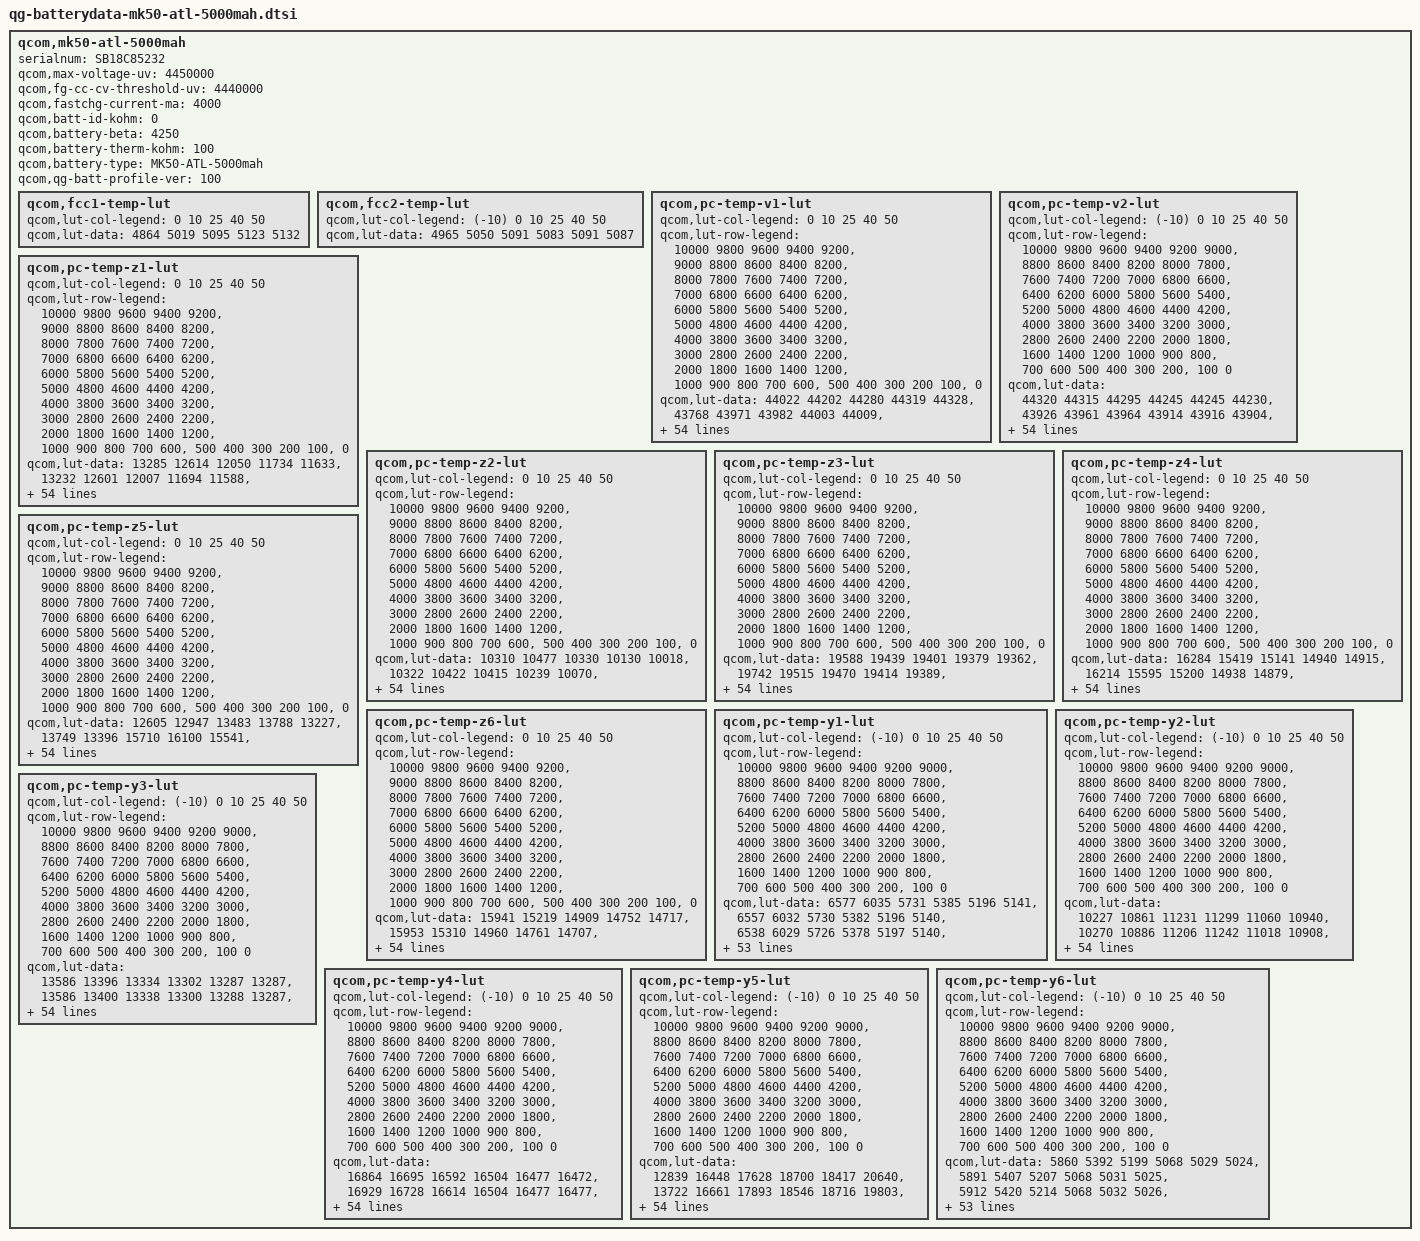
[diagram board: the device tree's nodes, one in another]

qcom,mk50-atl-5000mah {
    serialnum = "SB18C85232";
    qcom,max-voltage-uv = <4450000>;
    qcom,fg-cc-cv-threshold-uv = <4440000>;
    qcom,fastchg-current-ma = <4000>;
    qcom,batt-id-kohm = <0>;
    qcom,battery-beta = <4250>;
    qcom,battery-therm-kohm = <100>;
    qcom,battery-type = "MK50-ATL-5000mah";
    qcom,qg-batt-profile-ver = <100>;

	qcom,fcc1-temp-lut {
		qcom,lut-col-legend = <0 10 25 40 50>;
		qcom,lut-data = <4864 5019 5095 5123 5132>;
	};

	qcom,fcc2-temp-lut {
		qcom,lut-col-legend = <(-10) 0 10 25 40 50>;
		qcom,lut-data = <4965 5050 5091 5083 5091 5087>;
	};

	qcom,pc-temp-v1-lut {
		qcom,lut-col-legend = <0 10 25 40 50>;
		qcom,lut-row-legend = <10000 9800 9600 9400 9200>,
			<9000 8800 8600 8400 8200>,
			<8000 7800 7600 7400 7200>,
			<7000 6800 6600 6400 6200>,
			<6000 5800 5600 5400 5200>,
			<5000 4800 4600 4400 4200>,
			<4000 3800 3600 3400 3200>,
			<3000 2800 2600 2400 2200>,
			<2000 1800 1600 1400 1200>,
			<1000 900 800 700 600>,
			<500 400 300 200 100>,
			<0>;
		qcom,lut-data = <44022 44202 44280 44319 44328>,
			<43768 43971 43982 44003 44009>,
			<43525 43723 43742 43757 43756>,
			<43289 43479 43517 43532 43534>,
			<43052 43241 43282 43304 43310>,
			<42808 43001 43042 43072 43078>,
			<42564 42756 42801 42838 42844>,
			<42324 42509 42556 42596 42606>,
			<42088 42264 42310 42349 42365>,
			<41856 42022 42069 42108 42125>,
			<41628 41786 41831 41872 41886>,
			<41405 41555 41597 41639 41650>,
			<41191 41329 41369 41408 41419>,
			<40988 41112 41146 41180 41192>,
			<40786 40903 40930 40962 40973>,
			<40580 40701 40721 40750 40760>,
			<40375 40500 40521 40548 40556>,
			<40191 40304 40331 40354 40363>,
			<40024 40125 40149 40169 40179>,
			<39868 39967 39984 40000 40009>,
			<39719 39808 39826 39844 39851>,
			<39576 39635 39635 39655 39662>,
			<39423 39453 39393 39384 39384>,
			<39247 39243 39168 39130 39122>,
			<39066 38974 38987 38974 38976>,
			<38889 38760 38833 38854 38871>,
			<38711 38663 38720 38749 38767>,
			<38586 38597 38635 38655 38660>,
			<38515 38532 38557 38567 38560>,
			<38461 38468 38478 38475 38465>,
			<38413 38408 38405 38387 38378>,
			<38370 38349 38338 38311 38300>,
			<38331 38295 38279 38245 38231>,
			<38294 38245 38222 38183 38165>,
			<38258 38203 38172 38123 38101>,
			<38224 38163 38123 38067 38038>,
			<38194 38126 38076 38011 37976>,
			<38159 38088 38032 37959 37916>,
			<38106 38034 37974 37892 37842>,
			<38032 37952 37890 37798 37736>,
			<37942 37851 37788 37687 37613>,
			<37822 37734 37675 37576 37497>,
			<37683 37596 37542 37453 37374>,
			<37528 37428 37379 37296 37212>,
			<37361 37266 37219 37151 37070>,
			<37254 37153 37109 37053 36990>,
			<37203 37115 37071 37020 36961>,
			<37162 37085 37049 36994 36934>,
			<37128 37069 37026 36975 36913>,
			<37095 37033 36990 36926 36855>,
			<37033 36870 36796 36701 36604>,
			<36772 36442 36369 36268 36170>,
			<36265 35853 35792 35692 35593>,
			<35564 35011 35003 34907 34807>,
			<34395 33595 33776 33693 33587>,
			<30000 30000 30000 30000 30000>;
	};

	qcom,pc-temp-v2-lut {
		qcom,lut-col-legend = <(-10) 0 10 25 40 50>;
		qcom,lut-row-legend = <10000 9800 9600 9400 9200 9000>,
			<8800 8600 8400 8200 8000 7800>,
			<7600 7400 7200 7000 6800 6600>,
			<6400 6200 6000 5800 5600 5400>,
			<5200 5000 4800 4600 4400 4200>,
			<4000 3800 3600 3400 3200 3000>,
			<2800 2600 2400 2200 2000 1800>,
			<1600 1400 1200 1000 900 800>,
			<700 600 500 400 300 200>,
			<100 0>;
		qcom,lut-data = <44320 44315 44295 44245 44245 44230>,
			<43926 43961 43964 43914 43916 43904>,
			<43579 43644 43663 43612 43617 43608>,
			<43290 43373 43399 43347 43354 43346>,
			<43052 43141 43168 43113 43124 43117>,
			<42819 42910 42937 42881 42894 42888>,
			<42559 42663 42692 42637 42652 42649>,
			<42296 42415 42445 42392 42409 42408>,
			<42066 42168 42199 42149 42166 42167>,
			<41869 41921 41954 41906 41923 41924>,
			<41662 41685 41713 41669 41685 41686>,
			<41406 41463 41476 41436 41451 41452>,
			<41132 41248 41246 41209 41222 41223>,
			<40907 41037 41024 40987 40999 41000>,
			<40733 40830 40809 40769 40780 40782>,
			<40543 40614 40603 40560 40571 40573>,
			<40256 40380 40406 40357 40368 40370>,
			<39917 40139 40208 40164 40174 40176>,
			<39651 39898 39997 39988 39995 39996>,
			<39453 39657 39777 39822 39824 39823>,
			<39261 39429 39553 39631 39643 39645>,
			<39031 39217 39317 39397 39445 39459>,
			<38791 39020 39098 39165 39243 39267>,
			<38596 38844 38912 38964 39029 39050>,
			<38431 38683 38747 38782 38817 38830>,
			<38302 38532 38601 38633 38657 38666>,
			<38217 38386 38472 38510 38535 38543>,
			<38154 38254 38356 38403 38429 38436>,
			<38095 38137 38251 38303 38329 38335>,
			<38043 38032 38154 38212 38239 38242>,
			<37993 37962 38060 38129 38159 38158>,
			<37941 37917 37965 38054 38087 38083>,
			<37889 37880 37891 37984 38018 38010>,
			<37834 37843 37840 37920 37951 37942>,
			<37778 37808 37799 37860 37883 37873>,
			<37720 37765 37759 37795 37807 37789>,
			<37659 37710 37722 37728 37726 37691>,
			<37596 37648 37678 37657 37640 37593>,
			<37526 37581 37621 37587 37550 37499>,
			<37446 37506 37551 37512 37458 37406>,
			<37358 37420 37462 37427 37369 37318>,
			<37264 37318 37347 37329 37277 37228>,
			<37163 37196 37210 37208 37150 37096>,
			<37071 37050 37054 37073 37015 36956>,
			<36987 36890 36888 36946 36906 36853>,
			<36910 36770 36782 36873 36850 36798>,
			<36866 36731 36749 36858 36838 36786>,
			<36818 36693 36713 36840 36824 36770>,
			<36771 36658 36665 36816 36798 36744>,
			<36721 36610 36579 36758 36733 36660>,
			<36661 36520 36338 36531 36454 36360>,
			<36556 36220 35852 36064 35970 35861>,
			<36334 35595 35181 35437 35327 35210>,
			<35882 34640 34171 34600 34453 34322>,
			<35058 33288 32721 33351 33175 33035>,
			<34064 31548 27372 27953 28069 28049>;
	};

	qcom,pc-temp-z1-lut {
		qcom,lut-col-legend = <0 10 25 40 50>;
		qcom,lut-row-legend = <10000 9800 9600 9400 9200>,
			<9000 8800 8600 8400 8200>,
			<8000 7800 7600 7400 7200>,
			<7000 6800 6600 6400 6200>,
			<6000 5800 5600 5400 5200>,
			<5000 4800 4600 4400 4200>,
			<4000 3800 3600 3400 3200>,
			<3000 2800 2600 2400 2200>,
			<2000 1800 1600 1400 1200>,
			<1000 900 800 700 600>,
			<500 400 300 200 100>,
			<0>;
		qcom,lut-data = <13285 12614 12050 11734 11633>,
			<13232 12601 12007 11694 11588>,
			<13214 12565 11986 11681 11579>,
			<13203 12541 11970 11669 11570>,
			<13189 12529 11958 11660 11564>,
			<13166 12518 11944 11654 11560>,
			<13145 12506 11932 11649 11557>,
			<13140 12494 11922 11644 11555>,
			<13143 12482 11913 11639 11554>,
			<13144 12468 11907 11639 11554>,
			<13131 12456 11902 11640 11555>,
			<13107 12449 11900 11640 11557>,
			<13096 12444 11899 11640 11557>,
			<13085 12437 11898 11640 11558>,
			<13078 12427 11898 11640 11558>,
			<13075 12420 11899 11640 11559>,
			<13066 12420 11900 11640 11560>,
			<13061 12421 11901 11641 11561>,
			<13047 12421 11903 11643 11563>,
			<13036 12420 11906 11645 11565>,
			<13039 12420 11909 11647 11567>,
			<13044 12423 11911 11649 11569>,
			<13044 12429 11913 11649 11570>,
			<13037 12433 11914 11650 11571>,
			<13030 12435 11916 11651 11572>,
			<13030 12438 11920 11654 11575>,
			<13036 12443 11924 11657 11577>,
			<13041 12449 11928 11660 11581>,
			<13045 12453 11933 11664 11584>,
			<13052 12458 11938 11668 11587>,
			<13054 12461 11943 11671 11590>,
			<13064 12464 11948 11675 11594>,
			<13073 12469 11953 11679 11598>,
			<13079 12474 11958 11684 11603>,
			<13088 12479 11964 11689 11607>,
			<13090 12485 11971 11695 11612>,
			<13093 12490 11977 11701 11616>,
			<13098 12496 11983 11706 11621>,
			<13111 12504 11990 11710 11624>,
			<13136 12520 11997 11714 11627>,
			<13154 12533 12005 11718 11630>,
			<13171 12539 12014 11722 11633>,
			<13188 12546 12024 11726 11637>,
			<13216 12565 12034 11731 11639>,
			<13234 12580 12047 11738 11644>,
			<13227 12584 12057 11742 11647>,
			<13225 12570 12056 11742 11647>,
			<13227 12585 12058 11742 11646>,
			<13253 12577 12062 11745 11648>,
			<13268 12590 12063 11748 11652>,
			<13479 12587 12073 11756 11656>,
			<13241 12603 12093 11763 11664>,
			<13308 12628 12104 11774 11673>,
			<13306 12676 12125 11790 11688>,
			<13306 12676 12125 11790 11688>,
			<13306 12676 12125 11790 11688>;
	};

	qcom,pc-temp-z2-lut {
		qcom,lut-col-legend = <0 10 25 40 50>;
		qcom,lut-row-legend = <10000 9800 9600 9400 9200>,
			<9000 8800 8600 8400 8200>,
			<8000 7800 7600 7400 7200>,
			<7000 6800 6600 6400 6200>,
			<6000 5800 5600 5400 5200>,
			<5000 4800 4600 4400 4200>,
			<4000 3800 3600 3400 3200>,
			<3000 2800 2600 2400 2200>,
			<2000 1800 1600 1400 1200>,
			<1000 900 800 700 600>,
			<500 400 300 200 100>,
			<0>;
		qcom,lut-data = <10310 10477 10330 10130 10018>,
			<10322 10422 10415 10239 10070>,
			<10315 10441 10421 10306 10250>,
			<10293 10445 10427 10320 10289>,
			<10270 10409 10417 10319 10297>,
			<10250 10363 10381 10278 10275>,
			<10232 10336 10348 10237 10247>,
			<10223 10315 10322 10227 10226>,
			<10216 10303 10300 10220 10200>,
			<10211 10296 10283 10209 10190>,
			<10204 10292 10268 10191 10191>,
			<10198 10294 10265 10181 10193>,
			<10199 10303 10284 10190 10197>,
			<10208 10315 10310 10208 10205>,
			<10220 10344 10327 10224 10216>,
			<10231 10377 10342 10240 10240>,
			<10243 10401 10354 10256 10253>,
			<10262 10423 10364 10279 10248>,
			<10297 10443 10375 10296 10242>,
			<10337 10462 10391 10293 10242>,
			<10369 10479 10413 10278 10244>,
			<10398 10494 10455 10287 10261>,
			<10419 10507 10552 10541 10562>,
			<10434 10522 10614 10784 10869>,
			<10447 10541 10552 10659 10720>,
			<10458 10553 10450 10355 10308>,
			<10467 10544 10433 10270 10206>,
			<10475 10526 10451 10296 10513>,
			<10482 10522 10471 10334 10762>,
			<10487 10530 10492 10408 10705>,
			<10494 10539 10509 10501 10568>,
			<10502 10544 10511 10509 10459>,
			<10510 10549 10508 10452 10362>,
			<10517 10553 10505 10395 10286>,
			<10524 10560 10496 10353 10225>,
			<10532 10566 10487 10322 10182>,
			<10541 10573 10494 10327 10172>,
			<10551 10581 10520 10363 10176>,
			<10566 10593 10547 10406 10192>,
			<10586 10616 10578 10474 10326>,
			<10607 10638 10604 10529 10472>,
			<10629 10651 10613 10529 10495>,
			<10659 10665 10619 10518 10502>,
			<10710 10692 10623 10510 10500>,
			<11037 10849 10660 10491 10493>,
			<10848 11022 10715 10471 10302>,
			<10828 11020 10707 10386 10265>,
			<10763 11020 10697 10354 10265>,
			<10679 11554 10703 10396 10289>,
			<10585 11786 10777 10443 10346>,
			<10594 11737 10774 10395 10293>,
			<10508 11513 10721 10264 10100>,
			<10306 11264 10643 10154 10023>,
			<10104 10823 10566 10098 9962>,
			<10104 10823 10566 10098 9962>,
			<10104 10823 10566 10098 9962>;
	};

	qcom,pc-temp-z3-lut {
		qcom,lut-col-legend = <0 10 25 40 50>;
		qcom,lut-row-legend = <10000 9800 9600 9400 9200>,
			<9000 8800 8600 8400 8200>,
			<8000 7800 7600 7400 7200>,
			<7000 6800 6600 6400 6200>,
			<6000 5800 5600 5400 5200>,
			<5000 4800 4600 4400 4200>,
			<4000 3800 3600 3400 3200>,
			<3000 2800 2600 2400 2200>,
			<2000 1800 1600 1400 1200>,
			<1000 900 800 700 600>,
			<500 400 300 200 100>,
			<0>;
		qcom,lut-data = <19588 19439 19401 19379 19362>,
			<19742 19515 19470 19414 19389>,
			<19800 19586 19488 19439 19426>,
			<19832 19617 19497 19449 19433>,
			<19847 19628 19504 19454 19438>,
			<19855 19633 19511 19456 19446>,
			<19860 19633 19514 19458 19452>,
			<19859 19633 19513 19462 19452>,
			<19852 19632 19510 19466 19453>,
			<19846 19627 19507 19465 19453>,
			<19844 19621 19502 19456 19449>,
			<19842 19616 19496 19448 19444>,
			<19837 19612 19487 19445 19440>,
			<19825 19605 19478 19442 19436>,
			<19814 19595 19473 19439 19432>,
			<19809 19584 19470 19435 19428>,
			<19805 19576 19467 19430 19424>,
			<19798 19569 19462 19426 19418>,
			<19780 19564 19458 19422 19412>,
			<19762 19560 19453 19414 19404>,
			<19752 19557 19447 19403 19394>,
			<19744 19559 19449 19400 19391>,
			<19742 19564 19468 19420 19406>,
			<19749 19571 19481 19439 19421>,
			<19758 19583 19471 19426 19409>,
			<19761 19591 19451 19395 19376>,
			<19763 19585 19441 19382 19369>,
			<19763 19571 19435 19379 19398>,
			<19757 19564 19433 19377 19426>,
			<19746 19559 19438 19395 19435>,
			<19738 19557 19448 19425 19440>,
			<19730 19560 19455 19431 19440>,
			<19724 19564 19462 19429 19431>,
			<19718 19565 19465 19427 19420>,
			<19713 19564 19464 19422 19410>,
			<19708 19562 19462 19415 19398>,
			<19704 19559 19457 19407 19388>,
			<19698 19554 19450 19398 19378>,
			<19692 19549 19445 19394 19374>,
			<19684 19544 19442 19396 19375>,
			<19674 19538 19439 19397 19378>,
			<19664 19531 19434 19396 19382>,
			<19649 19522 19428 19394 19387>,
			<19624 19512 19423 19394 19393>,
			<19559 19483 19415 19390 19393>,
			<19320 19442 19399 19376 19375>,
			<19312 19440 19398 19366 19361>,
			<19308 19437 19390 19362 19354>,
			<19301 19304 19389 19352 19343>,
			<19296 19292 19365 19344 19338>,
			<19293 19297 19382 19358 19354>,
			<19297 19305 19394 19387 19379>,
			<19304 19308 19393 19389 19380>,
			<19327 19445 19395 19390 19382>,
			<19327 19445 19395 19390 19382>,
			<19327 19445 19395 19390 19382>;
	};

	qcom,pc-temp-z4-lut {
		qcom,lut-col-legend = <0 10 25 40 50>;
		qcom,lut-row-legend = <10000 9800 9600 9400 9200>,
			<9000 8800 8600 8400 8200>,
			<8000 7800 7600 7400 7200>,
			<7000 6800 6600 6400 6200>,
			<6000 5800 5600 5400 5200>,
			<5000 4800 4600 4400 4200>,
			<4000 3800 3600 3400 3200>,
			<3000 2800 2600 2400 2200>,
			<2000 1800 1600 1400 1200>,
			<1000 900 800 700 600>,
			<500 400 300 200 100>,
			<0>;
		qcom,lut-data = <16284 15419 15141 14940 14915>,
			<16214 15595 15200 14938 14879>,
			<16053 15438 15137 14954 14911>,
			<15791 15301 15026 14906 14877>,
			<15582 15189 14959 14868 14846>,
			<15436 15094 14911 14843 14824>,
			<15318 15027 14873 14820 14804>,
			<15226 14973 14844 14798 14786>,
			<15153 14931 14819 14778 14769>,
			<15091 14898 14799 14762 14755>,
			<15036 14871 14781 14749 14740>,
			<14990 14846 14768 14739 14730>,
			<14954 14826 14758 14732 14725>,
			<14925 14807 14750 14727 14722>,
			<14901 14788 14743 14721 14719>,
			<14883 14776 14736 14717 14715>,
			<14869 14776 14731 14712 14712>,
			<14856 14776 14727 14708 14709>,
			<14846 14774 14723 14704 14707>,
			<14835 14760 14718 14701 14702>,
			<14815 14748 14713 14699 14697>,
			<14790 14749 14715 14700 14697>,
			<14781 14753 14742 14737 14742>,
			<14788 14766 14777 14786 14798>,
			<14802 14825 14818 14820 14824>,
			<14826 14872 14857 14847 14843>,
			<14866 14870 14862 14853 14844>,
			<14886 14861 14852 14843 14799>,
			<14883 14851 14839 14827 14751>,
			<14875 14838 14822 14796 14730>,
			<14866 14823 14801 14755 14715>,
			<14853 14808 14781 14734 14707>,
			<14839 14793 14761 14722 14701>,
			<14827 14780 14747 14715 14698>,
			<14815 14770 14738 14710 14698>,
			<14803 14761 14732 14707 14697>,
			<14790 14754 14729 14705 14697>,
			<14777 14748 14727 14704 14696>,
			<14766 14744 14727 14704 14697>,
			<14755 14742 14729 14711 14707>,
			<14746 14739 14731 14718 14718>,
			<14738 14732 14729 14717 14713>,
			<14729 14721 14722 14711 14701>,
			<14714 14710 14716 14709 14701>,
			<14705 14688 14697 14700 14693>,
			<14908 14682 14677 14679 14672>,
			<14912 14674 14671 14682 14677>,
			<14912 14670 14664 14675 14672>,
			<14915 14811 14649 14661 14657>,
			<14912 14813 14660 14651 14642>,
			<14906 14810 14657 14669 14672>,
			<14906 14819 14665 14669 14680>,
			<14921 14821 14672 14675 14687>,
			<14923 14685 14673 14679 14690>,
			<14923 14685 14673 14679 14690>,
			<14923 14685 14673 14679 14690>;
	};

	qcom,pc-temp-z5-lut {
		qcom,lut-col-legend = <0 10 25 40 50>;
		qcom,lut-row-legend = <10000 9800 9600 9400 9200>,
			<9000 8800 8600 8400 8200>,
			<8000 7800 7600 7400 7200>,
			<7000 6800 6600 6400 6200>,
			<6000 5800 5600 5400 5200>,
			<5000 4800 4600 4400 4200>,
			<4000 3800 3600 3400 3200>,
			<3000 2800 2600 2400 2200>,
			<2000 1800 1600 1400 1200>,
			<1000 900 800 700 600>,
			<500 400 300 200 100>,
			<0>;
		qcom,lut-data = <12605 12947 13483 13788 13227>,
			<13749 13396 15710 16100 15541>,
			<14352 14908 16525 17513 18495>,
			<14741 15897 17156 18685 19441>,
			<15125 16350 17811 19361 20414>,
			<15561 16744 18481 19689 21616>,
			<16010 17240 19076 20053 22728>,
			<16437 17777 19624 21102 23582>,
			<16838 18303 20088 22514 24321>,
			<17322 18792 20472 22855 25178>,
			<18054 19319 20936 22862 26255>,
			<18912 19959 21129 22880 27225>,
			<19617 20694 21353 23390 27881>,
			<20170 21504 21706 24346 28450>,
			<20837 22578 22195 25105 29182>,
			<22176 23312 22974 25784 30137>,
			<23791 23396 23675 26503 30747>,
			<24373 23426 24267 27511 30850>,
			<24239 23558 24879 28297 30791>,
			<24164 24325 25471 27877 30557>,
			<25218 25638 26162 26417 29826>,
			<28133 28343 28737 26469 29838>,
			<32005 32774 39651 37088 37823>,
			<39531 36746 47218 47218 46030>,
			<47125 40891 40415 40775 39820>,
			<49679 43302 28271 24835 23328>,
			<50885 39724 23477 18717 18257>,
			<50830 32173 21249 17265 20485>,
			<47469 28922 20438 16686 23509>,
			<42579 27725 20985 18700 26775>,
			<39941 27206 22157 22689 30118>,
			<38221 28214 23729 24916 31184>,
			<37243 30566 26178 26225 30967>,
			<36932 32546 28632 27330 30312>,
			<36828 34380 31404 28579 29332>,
			<36961 35747 33430 29509 28310>,
			<37368 36542 33574 29481 27585>,
			<37986 37125 33532 29022 26556>,
			<39316 37343 33457 28869 26180>,
			<41324 37298 33174 30474 28174>,
			<42024 37018 32634 32190 30370>,
			<41596 35361 30662 30378 30121>,
			<40791 33705 27970 26564 29276>,
			<38701 33793 28093 27532 32556>,
			<33962 34155 29902 28021 35161>,
			<12940 27877 28677 25251 28119>,
			<12693 27690 28754 21190 20995>,
			<12570 26683 26288 21163 19826>,
			<12360 12805 28443 20613 19896>,
			<12253 12454 21035 21041 22250>,
			<12252 12646 25320 23505 24773>,
			<12340 12688 23136 23556 22283>,
			<12253 12697 20989 21298 19483>,
			<12767 24950 20244 19191 17499>,
			<12767 24950 20244 19191 17499>,
			<12767 24950 20244 19191 17499>;
	};

	qcom,pc-temp-z6-lut {
		qcom,lut-col-legend = <0 10 25 40 50>;
		qcom,lut-row-legend = <10000 9800 9600 9400 9200>,
			<9000 8800 8600 8400 8200>,
			<8000 7800 7600 7400 7200>,
			<7000 6800 6600 6400 6200>,
			<6000 5800 5600 5400 5200>,
			<5000 4800 4600 4400 4200>,
			<4000 3800 3600 3400 3200>,
			<3000 2800 2600 2400 2200>,
			<2000 1800 1600 1400 1200>,
			<1000 900 800 700 600>,
			<500 400 300 200 100>,
			<0>;
		qcom,lut-data = <15941 15219 14909 14752 14717>,
			<15953 15310 14960 14761 14707>,
			<15911 15267 14935 14775 14735>,
			<15788 15222 14891 14760 14724>,
			<15682 15170 14864 14747 14715>,
			<15609 15121 14844 14736 14709>,
			<15547 15086 14827 14727 14703>,
			<15496 15057 14812 14720 14697>,
			<15451 15032 14799 14713 14691>,
			<15414 15011 14787 14705 14684>,
			<15383 14992 14776 14695 14676>,
			<15356 14976 14766 14687 14670>,
			<15331 14962 14756 14682 14665>,
			<15308 14948 14748 14677 14661>,
			<15288 14933 14742 14673 14657>,
			<15272 14922 14738 14668 14654>,
			<15259 14916 14733 14664 14650>,
			<15244 14912 14729 14660 14645>,
			<15228 14907 14725 14656 14640>,
			<15212 14899 14720 14650 14634>,
			<15198 14894 14716 14643 14627>,
			<15184 14895 14718 14643 14625>,
			<15180 14900 14740 14673 14656>,
			<15187 14910 14762 14702 14687>,
			<15199 14944 14773 14703 14687>,
			<15213 14969 14780 14702 14681>,
			<15233 14966 14780 14700 14676>,
			<15242 14956 14774 14694 14673>,
			<15239 14948 14767 14687 14670>,
			<15231 14942 14764 14685 14666>,
			<15224 14936 14760 14683 14663>,
			<15216 14932 14757 14679 14659>,
			<15209 14928 14753 14674 14653>,
			<15202 14925 14749 14669 14647>,
			<15196 14921 14746 14665 14641>,
			<15191 14917 14743 14661 14636>,
			<15185 14914 14739 14657 14631>,
			<15182 14912 14736 14651 14625>,
			<15180 14910 14734 14650 14623>,
			<15179 14910 14735 14653 14628>,
			<15178 14909 14736 14657 14634>,
			<15178 14906 14734 14656 14634>,
			<15177 14901 14730 14653 14632>,
			<15169 14897 14727 14653 14635>,
			<15137 14880 14718 14648 14632>,
			<15120 14862 14703 14632 14614>,
			<15117 14857 14700 14629 14609>,
			<15115 14854 14694 14623 14603>,
			<15115 14848 14687 14612 14591>,
			<15115 14846 14681 14603 14581>,
			<15117 14851 14691 14619 14603>,
			<15128 14866 14704 14637 14623>,
			<15152 14877 14711 14644 14630>,
			<15184 14903 14719 14650 14636>,
			<15184 14903 14719 14650 14636>,
			<15184 14903 14719 14650 14636>;
	};

	qcom,pc-temp-y1-lut {
		qcom,lut-col-legend = <(-10) 0 10 25 40 50>;
		qcom,lut-row-legend = <10000 9800 9600 9400 9200 9000>,
			<8800 8600 8400 8200 8000 7800>,
			<7600 7400 7200 7000 6800 6600>,
			<6400 6200 6000 5800 5600 5400>,
			<5200 5000 4800 4600 4400 4200>,
			<4000 3800 3600 3400 3200 3000>,
			<2800 2600 2400 2200 2000 1800>,
			<1600 1400 1200 1000 900 800>,
			<700 600 500 400 300 200>,
			<100 0>;
		qcom,lut-data = <6577 6035 5731 5385 5196 5141>,
			<6557 6032 5730 5382 5196 5140>,
			<6538 6029 5726 5378 5197 5140>,
			<6520 6024 5721 5374 5197 5140>,
			<6507 6021 5717 5370 5196 5140>,
			<6499 6019 5715 5367 5196 5139>,
			<6498 6019 5711 5364 5196 5139>,
			<6499 6018 5707 5361 5195 5139>,
			<6501 6019 5705 5360 5195 5139>,
			<6503 6022 5702 5359 5194 5138>,
			<6504 6023 5700 5357 5193 5138>,
			<6513 6023 5698 5356 5192 5138>,
			<6527 6023 5696 5355 5192 5138>,
			<6531 6023 5693 5354 5192 5138>,
			<6536 6022 5690 5353 5192 5140>,
			<6542 6022 5689 5353 5192 5140>,
			<6547 6033 5693 5355 5193 5141>,
			<6551 6045 5698 5357 5193 5142>,
			<6549 6044 5698 5360 5194 5142>,
			<6532 6036 5695 5363 5195 5144>,
			<6519 6035 5695 5365 5197 5145>,
			<6523 6045 5701 5367 5198 5146>,
			<6531 6057 5707 5369 5200 5147>,
			<6535 6056 5711 5372 5203 5148>,
			<6538 6050 5716 5376 5205 5150>,
			<6540 6048 5718 5381 5207 5152>,
			<6534 6054 5717 5385 5210 5155>,
			<6522 6059 5716 5390 5213 5157>,
			<6520 6056 5722 5396 5216 5160>,
			<6526 6049 5729 5401 5219 5162>,
			<6532 6047 5732 5406 5223 5165>,
			<6525 6059 5734 5410 5227 5168>,
			<6508 6070 5734 5415 5230 5170>,
			<6502 6065 5736 5419 5234 5173>,
			<6501 6050 5738 5423 5237 5176>,
			<6501 6046 5740 5428 5239 5178>,
			<6503 6051 5741 5433 5241 5178>,
			<6509 6055 5743 5436 5242 5179>,
			<6512 6056 5748 5439 5244 5181>,
			<6518 6058 5753 5441 5245 5183>,
			<6525 6060 5757 5445 5246 5184>,
			<6525 6065 5765 5449 5247 5185>,
			<6521 6067 5770 5453 5249 5186>,
			<6518 6073 5783 5459 5252 5189>,
			<6527 6095 5786 5465 5257 5193>,
			<6578 6106 5785 5473 5262 5195>,
			<6602 6131 5784 5478 5261 5195>,
			<6598 6104 5783 5481 5259 5195>,
			<6606 6130 5790 5481 5259 5196>,
			<6605 6136 5794 5477 5259 5196>,
			<6641 6158 5805 5476 5262 5198>,
			<6743 6214 5841 5485 5267 5203>,
			<6801 6296 5913 5512 5275 5210>,
			<6849 6295 5988 5542 5286 5220>,
			<6849 6295 5988 5542 5286 5220>,
			<6849 6295 5988 5542 5286 5220>;
	};

	qcom,pc-temp-y2-lut {
		qcom,lut-col-legend = <(-10) 0 10 25 40 50>;
		qcom,lut-row-legend = <10000 9800 9600 9400 9200 9000>,
			<8800 8600 8400 8200 8000 7800>,
			<7600 7400 7200 7000 6800 6600>,
			<6400 6200 6000 5800 5600 5400>,
			<5200 5000 4800 4600 4400 4200>,
			<4000 3800 3600 3400 3200 3000>,
			<2800 2600 2400 2200 2000 1800>,
			<1600 1400 1200 1000 900 800>,
			<700 600 500 400 300 200>,
			<100 0>;
		qcom,lut-data = <10227 10861 11231 11299 11060 10940>,
			<10270 10886 11206 11242 11018 10908>,
			<10340 10903 11180 11186 10973 10852>,
			<10417 10914 11154 11133 10930 10789>,
			<10482 10919 11128 11088 10894 10738>,
			<10514 10921 11102 11055 10870 10715>,
			<10519 10912 11074 11032 10856 10710>,
			<10522 10901 11047 11014 10846 10706>,
			<10544 10901 11026 10999 10837 10694>,
			<10644 10909 11007 10985 10824 10670>,
			<10729 10920 11001 10974 10816 10656>,
			<10751 10931 11008 10964 10809 10652>,
			<10765 10946 11022 10958 10800 10649>,
			<10781 10987 11046 10962 10791 10653>,
			<10796 11080 11091 10978 10781 10667>,
			<10818 11148 11136 11001 10779 10683>,
			<10876 11187 11184 11052 10800 10699>,
			<10960 11213 11230 11119 10837 10721>,
			<11001 11217 11274 11192 10894 10757>,
			<11021 11216 11316 11270 10982 10821>,
			<11030 11217 11329 11303 11076 10916>,
			<10673 11222 11331 11316 11201 11116>,
			<9934 11229 11334 11321 11275 11254>,
			<9699 11240 11342 11309 11225 11171>,
			<9688 11256 11358 11285 11132 11011>,
			<9682 11259 11374 11283 11115 10980>,
			<9678 11221 11396 11311 11139 11035>,
			<9675 11185 11409 11345 11172 11089>,
			<9673 11207 11411 11378 11210 11116>,
			<9671 11264 11412 11413 11253 11139>,
			<9669 11279 11414 11434 11290 11162>,
			<9668 11223 11417 11450 11329 11187>,
			<9666 11142 11418 11458 11356 11222>,
			<9665 11075 11404 11456 11375 11301>,
			<9664 10998 11379 11452 11389 11381>,
			<9664 10817 11351 11444 11375 11379>,
			<9663 10203 11315 11425 11321 11324>,
			<9662 9727 11274 11402 11282 11262>,
			<9662 9695 11226 11378 11240 11188>,
			<9662 9682 11167 11351 11204 11129>,
			<9662 9674 11088 11316 11207 11133>,
			<9662 9669 10982 11278 11222 11152>,
			<9662 9666 10860 11271 11198 11085>,
			<9661 9664 10716 11264 11113 10938>,
			<9661 9662 10406 11246 10956 10824>,
			<9660 9661 9940 11136 10915 10737>,
			<9659 9660 9806 11113 10906 10761>,
			<9658 9659 9720 11093 10929 10801>,
			<9657 9658 9686 11086 10954 10851>,
			<9656 9657 9672 11109 10978 10841>,
			<9652 9654 9664 11093 10929 10754>,
			<9650 9651 9658 11022 10860 10648>,
			<9649 9649 9653 10917 10754 10584>,
			<9648 9648 9652 10803 10638 10491>,
			<9648 9648 9652 10803 10638 10491>,
			<9648 9648 9652 10803 10638 10491>;
	};

	qcom,pc-temp-y3-lut {
		qcom,lut-col-legend = <(-10) 0 10 25 40 50>;
		qcom,lut-row-legend = <10000 9800 9600 9400 9200 9000>,
			<8800 8600 8400 8200 8000 7800>,
			<7600 7400 7200 7000 6800 6600>,
			<6400 6200 6000 5800 5600 5400>,
			<5200 5000 4800 4600 4400 4200>,
			<4000 3800 3600 3400 3200 3000>,
			<2800 2600 2400 2200 2000 1800>,
			<1600 1400 1200 1000 900 800>,
			<700 600 500 400 300 200>,
			<100 0>;
		qcom,lut-data = <13586 13396 13334 13302 13287 13287>,
			<13586 13400 13338 13300 13288 13287>,
			<13585 13405 13341 13300 13289 13287>,
			<13583 13410 13344 13301 13291 13287>,
			<13581 13413 13347 13301 13292 13288>,
			<13579 13416 13349 13301 13293 13289>,
			<13575 13418 13351 13302 13295 13290>,
			<13571 13419 13353 13303 13296 13292>,
			<13572 13419 13354 13304 13296 13293>,
			<13584 13418 13355 13305 13297 13293>,
			<13592 13418 13356 13306 13297 13293>,
			<13553 13426 13355 13308 13298 13294>,
			<13483 13437 13354 13311 13299 13294>,
			<13468 13430 13353 13311 13299 13295>,
			<13483 13401 13350 13310 13300 13296>,
			<13495 13388 13349 13310 13300 13296>,
			<13486 13396 13348 13309 13300 13297>,
			<13467 13405 13348 13309 13300 13297>,
			<13452 13402 13347 13309 13301 13298>,
			<13440 13389 13345 13311 13303 13300>,
			<13433 13379 13342 13311 13303 13301>,
			<13433 13373 13337 13309 13302 13300>,
			<13433 13368 13332 13306 13300 13298>,
			<13432 13363 13328 13302 13295 13294>,
			<13424 13359 13326 13299 13290 13288>,
			<13416 13355 13324 13298 13289 13286>,
			<13422 13353 13323 13297 13289 13287>,
			<13440 13350 13321 13297 13288 13288>,
			<13463 13343 13321 13296 13287 13287>,
			<13494 13331 13320 13296 13286 13286>,
			<13531 13327 13318 13296 13285 13284>,
			<13570 13331 13315 13296 13286 13283>,
			<13614 13336 13314 13295 13286 13282>,
			<13660 13341 13316 13296 13286 13284>,
			<13712 13347 13318 13296 13287 13287>,
			<13765 13356 13320 13296 13287 13287>,
			<13819 13371 13323 13296 13288 13286>,
			<13874 13390 13325 13295 13288 13285>,
			<13921 13414 13328 13296 13288 13285>,
			<13960 13446 13332 13298 13289 13286>,
			<13996 13486 13334 13298 13290 13288>,
			<14027 13541 13337 13298 13291 13289>,
			<14056 13608 13340 13300 13290 13288>,
			<14093 13691 13344 13300 13288 13285>,
			<14150 13782 13341 13298 13286 13285>,
			<14214 13833 13348 13301 13294 13291>,
			<14231 13940 13368 13306 13298 13294>,
			<14346 14054 13404 13310 13300 13296>,
			<14503 14201 13457 13316 13302 13298>,
			<14772 14383 13541 13319 13302 13297>,
			<15594 14788 13701 13314 13296 13292>,
			<18320 16801 14113 13315 13297 13294>,
			<26236 25265 15283 13324 13300 13299>,
			<59838 65535 21746 13338 13313 13313>,
			<59838 65535 21746 13338 13313 13313>,
			<59838 65535 21746 13338 13313 13313>;
	};

	qcom,pc-temp-y4-lut {
		qcom,lut-col-legend = <(-10) 0 10 25 40 50>;
		qcom,lut-row-legend = <10000 9800 9600 9400 9200 9000>,
			<8800 8600 8400 8200 8000 7800>,
			<7600 7400 7200 7000 6800 6600>,
			<6400 6200 6000 5800 5600 5400>,
			<5200 5000 4800 4600 4400 4200>,
			<4000 3800 3600 3400 3200 3000>,
			<2800 2600 2400 2200 2000 1800>,
			<1600 1400 1200 1000 900 800>,
			<700 600 500 400 300 200>,
			<100 0>;
		qcom,lut-data = <16864 16695 16592 16504 16477 16472>,
			<16929 16728 16614 16504 16477 16477>,
			<17028 16780 16636 16505 16478 16479>,
			<17134 16837 16656 16507 16478 16481>,
			<17219 16882 16669 16508 16478 16482>,
			<17255 16899 16674 16508 16478 16482>,
			<17250 16894 16669 16509 16477 16480>,
			<17238 16888 16663 16510 16477 16478>,
			<17226 16888 16659 16511 16477 16478>,
			<17212 16890 16656 16514 16479 16479>,
			<17204 16891 16655 16517 16481 16479>,
			<17255 16888 16662 16520 16483 16481>,
			<17346 16884 16674 16524 16487 16484>,
			<17365 16909 16692 16531 16491 16486>,
			<17334 16999 16718 16542 16497 16489>,
			<17284 17041 16742 16555 16503 16492>,
			<17176 16985 16765 16572 16511 16497>,
			<17023 16903 16779 16592 16521 16504>,
			<16953 16853 16770 16619 16539 16514>,
			<16929 16814 16742 16651 16561 16527>,
			<16906 16779 16709 16656 16568 16539>,
			<16871 16747 16661 16618 16569 16554>,
			<16830 16717 16619 16571 16569 16563>,
			<16800 16693 16594 16536 16542 16538>,
			<16773 16672 16575 16506 16493 16491>,
			<16758 16647 16564 16499 16481 16478>,
			<16760 16608 16557 16499 16480 16475>,
			<16765 16579 16552 16498 16480 16474>,
			<16766 16571 16547 16501 16484 16478>,
			<16764 16566 16543 16506 16494 16486>,
			<16761 16566 16534 16512 16503 16495>,
			<16765 16574 16518 16518 16513 16507>,
			<16774 16586 16509 16522 16520 16516>,
			<16782 16599 16512 16523 16525 16522>,
			<16787 16616 16519 16524 16528 16525>,
			<16791 16639 16530 16522 16526 16523>,
			<16794 16683 16550 16512 16517 16514>,
			<16796 16718 16571 16506 16509 16508>,
			<16796 16731 16592 16504 16500 16505>,
			<16791 16739 16611 16504 16493 16503>,
			<16785 16742 16623 16506 16496 16508>,
			<16780 16741 16631 16514 16503 16519>,
			<16776 16733 16632 16511 16492 16502>,
			<16778 16708 16630 16504 16473 16472>,
			<16780 16683 16609 16491 16461 16457>,
			<16773 16667 16628 16495 16472 16484>,
			<16762 16673 16645 16510 16503 16525>,
			<16772 16689 16672 16535 16543 16566>,
			<16781 16708 16705 16575 16582 16606>,
			<16798 16737 16750 16607 16600 16607>,
			<16870 16773 16769 16568 16518 16525>,
			<17291 16999 16785 16546 16493 16500>,
			<18627 19138 16966 16564 16496 16498>,
			<29768 56979 20897 16613 16512 16508>,
			<29768 56979 20897 16613 16512 16508>,
			<29768 56979 20897 16613 16512 16508>;
	};

	qcom,pc-temp-y5-lut {
		qcom,lut-col-legend = <(-10) 0 10 25 40 50>;
		qcom,lut-row-legend = <10000 9800 9600 9400 9200 9000>,
			<8800 8600 8400 8200 8000 7800>,
			<7600 7400 7200 7000 6800 6600>,
			<6400 6200 6000 5800 5600 5400>,
			<5200 5000 4800 4600 4400 4200>,
			<4000 3800 3600 3400 3200 3000>,
			<2800 2600 2400 2200 2000 1800>,
			<1600 1400 1200 1000 900 800>,
			<700 600 500 400 300 200>,
			<100 0>;
		qcom,lut-data = <12839 16448 17628 18700 18417 20640>,
			<13722 16661 17893 18546 18716 19803>,
			<14678 16887 18083 18044 18914 19246>,
			<15599 17103 18209 17398 19030 18918>,
			<16376 17289 18283 16813 19084 18774>,
			<16901 17421 18317 16492 19096 18765>,
			<17144 17524 18294 16224 19080 19120>,
			<17328 17596 18222 15920 19010 19555>,
			<17938 17527 18094 15700 18748 19438>,
			<19890 17209 17815 15430 18119 18769>,
			<21223 17052 17454 15326 17591 18158>,
			<19500 17955 16911 15429 17259 17653>,
			<16400 19099 16295 15543 16928 17193>,
			<16182 18827 15719 15355 16487 16872>,
			<20169 17372 15158 14735 15955 16603>,
			<23252 16758 15073 14312 15454 16275>,
			<22436 19884 16413 14071 14903 15754>,
			<20791 23497 18297 13939 14556 15356>,
			<20471 23498 20004 14336 14585 15284>,
			<21522 22460 21692 15612 14731 15269>,
			<22384 22022 22405 17260 15321 15596>,
			<20904 22192 22705 20128 18698 18353>,
			<17421 22470 22836 22090 21296 20580>,
			<15080 22726 22772 21810 21003 20433>,
			<13455 23018 22653 21121 20312 20069>,
			<12545 23418 22639 20731 19836 19922>,
			<12467 24189 22743 20500 19402 19885>,
			<12435 24777 22923 20363 18891 19806>,
			<12454 22485 23647 20224 17797 18728>,
			<12746 16880 24580 20077 16602 16959>,
			<13049 15016 24347 20150 16466 16107>,
			<13136 15283 22565 20530 16756 15588>,
			<13187 15669 21400 21053 17180 15401>,
			<13265 16253 21389 22053 17899 16889>,
			<13414 17049 21512 23072 18929 19136>,
			<13603 17116 21305 23114 20350 20064>,
			<13861 15699 20786 22680 22330 20547>,
			<14191 14539 20333 22265 23208 20997>,
			<14335 14589 19916 22030 23023 21511>,
			<14356 14738 19472 21762 22709 21955>,
			<14333 14764 19056 20890 22438 22210>,
			<14058 14660 18636 19470 22039 22418>,
			<13430 14662 18169 19875 22493 23097>,
			<13031 14767 17825 20281 22142 23019>,
			<12879 14300 16712 19361 18522 19729>,
			<13088 13817 14743 18652 18860 17415>,
			<13056 13908 14494 18650 18229 15979>,
			<13006 13648 14310 18301 16939 15246>,
			<13103 13794 14170 18222 16399 15137>,
			<13161 13794 14266 18348 16368 14836>,
			<12883 14050 14164 18573 17017 15482>,
			<11186 12023 13923 19244 17447 15721>,
			<9889 9738 12655 19674 17342 15914>,
			<9144 8872 9662 20797 23156 23297>,
			<9144 8872 9662 20797 23156 23297>,
			<9144 8872 9662 20797 23156 23297>;
	};

	qcom,pc-temp-y6-lut {
		qcom,lut-col-legend = <(-10) 0 10 25 40 50>;
		qcom,lut-row-legend = <10000 9800 9600 9400 9200 9000>,
			<8800 8600 8400 8200 8000 7800>,
			<7600 7400 7200 7000 6800 6600>,
			<6400 6200 6000 5800 5600 5400>,
			<5200 5000 4800 4600 4400 4200>,
			<4000 3800 3600 3400 3200 3000>,
			<2800 2600 2400 2200 2000 1800>,
			<1600 1400 1200 1000 900 800>,
			<700 600 500 400 300 200>,
			<100 0>;
		qcom,lut-data = <5860 5392 5199 5068 5029 5024>,
			<5891 5407 5207 5068 5031 5025>,
			<5912 5420 5214 5068 5032 5026>,
			<5925 5431 5218 5068 5034 5027>,
			<5932 5438 5220 5069 5035 5028>,
			<5934 5440 5221 5069 5036 5029>,
			<5926 5437 5219 5069 5036 5029>,
			<5913 5432 5216 5070 5037 5030>,
			<5911 5429 5213 5071 5038 5030>,
			<5913 5427 5211 5072 5039 5031>,
			<5914 5426 5210 5073 5040 5032>,
			<5904 5428 5211 5075 5041 5032>,
			<5886 5432 5212 5078 5042 5034>,
			<5883 5436 5215 5081 5044 5035>,
			<5888 5442 5219 5083 5046 5036>,
			<5893 5444 5224 5087 5048 5038>,
			<5866 5436 5230 5091 5050 5040>,
			<5814 5421 5235 5096 5053 5042>,
			<5792 5406 5232 5104 5059 5045>,
			<5788 5387 5222 5114 5066 5051>,
			<5783 5373 5210 5116 5068 5054>,
			<5767 5362 5193 5104 5067 5057>,
			<5747 5353 5179 5088 5066 5058>,
			<5741 5348 5170 5076 5055 5048>,
			<5742 5343 5164 5066 5037 5030>,
			<5743 5339 5162 5064 5033 5026>,
			<5754 5334 5160 5064 5033 5026>,
			<5782 5330 5160 5064 5033 5026>,
			<5812 5331 5160 5065 5034 5026>,
			<5845 5332 5160 5067 5036 5028>,
			<5882 5335 5160 5069 5038 5029>,
			<5920 5351 5156 5071 5041 5032>,
			<5961 5375 5154 5073 5044 5035>,
			<6004 5401 5158 5075 5046 5038>,
			<6049 5435 5166 5076 5047 5041>,
			<6095 5471 5175 5076 5047 5041>,
			<6139 5512 5188 5073 5045 5037>,
			<6182 5557 5203 5072 5043 5035>,
			<6219 5606 5221 5073 5041 5035>,
			<6251 5662 5242 5074 5040 5035>,
			<6280 5719 5265 5076 5041 5037>,
			<6305 5781 5290 5079 5045 5042>,
			<6330 5847 5318 5080 5041 5036>,
			<6364 5921 5350 5081 5034 5026>,
			<6416 5999 5352 5077 5030 5023>,
			<6475 6045 5395 5082 5039 5035>,
			<6499 6137 5441 5091 5052 5049>,
			<6599 6240 5507 5102 5064 5063>,
			<6740 6372 5593 5118 5077 5076>,
			<6989 6535 5716 5129 5082 5075>,
			<7704 6895 5893 5114 5054 5048>,
			<9949 8559 6267 5111 5049 5043>,
			<15953 15206 7292 5130 5054 5047>,
			<38195 55138 13184 5165 5068 5061>,
			<38195 55138 13184 5165 5068 5061>,
			<38195 55138 13184 5165 5068 5061>;
	};

};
